# NV32F100 register map
File version: 1.6
Registers are 32-bit, read-write, reset 0x0 unless marked. A register's access mark holds for its fields unless they carry their own. Offsets are from the block's base; [hi:lo] are bit positions; {n}, {i} and the like mark numbered series.

## SMC — System Mode Controller
Base 0x4007E000; register names take the prefix SMC_
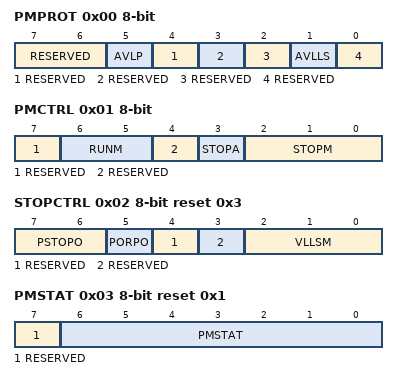
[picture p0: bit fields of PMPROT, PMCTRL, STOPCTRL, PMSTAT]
0x00 PMPROT 8-bit — Power Mode Protection register
  [7:6] RESERVED ro
  [5] AVLP — Allow Very-Low-Power Modes
    0=VLPR, VLPW and VLPS are not allowed; 1=VLPR, VLPW and VLPS are allowed
  [4] RESERVED ro
  [3] RESERVED ro
  [2] RESERVED ro
  [1] AVLLS — Allow Very-Low-Leakage Stop Mode
    0=Any VLLSx mode is not allowed; 1=Any VLLSx mode is allowed
  [0] RESERVED ro
0x01 PMCTRL 8-bit — Power Mode Control register
  [7] RESERVED ro
  [6:5] RUNM — Run Mode Control
    0=Normal Run mode (RUN); 2=Very-Low-Power Run mode (VLPR)
  [4] RESERVED ro
  [3] STOPA ro — Stop Aborted
    0=The previous stop mode entry was successsful; 1=The previous stop mode entry was aborted
  [2:0] STOPM — Stop Mode Control
    0=Normal Stop (STOP); 2=Very-Low-Power Stop (VLPS); 4=Very-Low-Leakage Stop (VLLSx); 6=Reseved
0x02 STOPCTRL 8-bit reset 0x3 — Stop Control Register
  [7:6] PSTOPO — Partial Stop Option
    0=STOP - Normal Stop mode; 1=PSTOP1 - Partial Stop with both system and bus clocks disabled; 2=PSTOP2 - Partial Stop with system clock disabled and bus clock enabled
  [5] PORPO — POR Power Option
    0=POR detect circuit is enabled in VLLS0; 1=POR detect circuit is disabled in VLLS0
  [4] RESERVED ro
  [3] RESERVED ro
  [2:0] VLLSM — VLLS Mode Control.
    0=VLLS0; 1=VLLS1; 3=VLLS3
0x03 PMSTAT 8-bit ro reset 0x1 — Power Mode Status register
  [7] RESERVED, [6:0] PMSTAT

## RCM — Reset Control Module
Base 0x4007F000; register names take the prefix RCM_
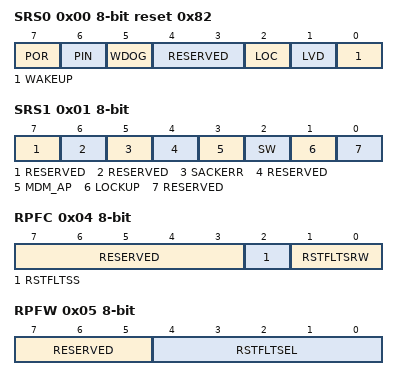
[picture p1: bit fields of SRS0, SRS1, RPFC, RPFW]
0x00 SRS0 8-bit ro reset 0x82 — System Reset Status Register 0
  [7] POR — Power-On Reset
    0=Reset not caused by POR; 1=Reset caused by POR
  [6] PIN — External Reset Pin
    0=Reset not caused by external reset pin; 1=Reset caused by external reset pin
  [5] WDOG — Watchdog
    0=Reset not caused by watchdog timeout; 1=Reset caused by watchdog timeout
  [4:3] RESERVED
  [2] LOC — Loss-of-Clock Reset
    0=Reset not caused by a loss of external clock; 1=Reset caused by a loss of external clock
  [1] LVD — Low-Voltage Detect Reset
    0=Reset not caused by LVD trip or POR; 1=Reset caused by LVD trip or POR
  [0] WAKEUP — Low Leakage Wakeup Reset
    0=Reset not caused by wakeup source; 1=Reset caused by wakeup source
0x01 SRS1 8-bit ro — System Reset Status Register 1
  [7] RESERVED
  [6] RESERVED
  [5] SACKERR — Stop Mode Acknowledge Error Reset
    0=Reset not caused by peripheral failure to acknowledge attempt to enter stop mode; 1=Reset caused by peripheral failure to acknowledge attempt to enter stop mode
  [4] RESERVED
  [3] MDM_AP — MDM-AP System Reset Request
    0=Reset not caused by host debugger system setting of the System Reset Request bit; 1=Reset caused by host debugger system setting of the System Reset Request bit
  [2] SW — Software
    0=Reset not caused by software setting of SYSRESETREQ bit; 1=Reset caused by software setting of SYSRESETREQ bit
  [1] LOCKUP — Core Lockup
    0=Reset not caused by core LOCKUP event; 1=Reset caused by core LOCKUP event
  [0] RESERVED
0x04 RPFC 8-bit — Reset Pin Filter Control register
  [7:3] RESERVED ro
  [2] RSTFLTSS — Reset Pin Filter Select in Stop Mode
    0=All filtering disabled; 1=LPO clock filter enabled
  [1:0] RSTFLTSRW — Reset Pin Filter Select in Run and Wait Modes
    0=All filtering disabled; 1=Bus clock filter enabled for normal operation; 2=LPO clock filter enabled for normal operation
0x05 RPFW 8-bit — Reset Pin Filter Width register
  [7:5] RESERVED ro
  [4:0] RSTFLTSEL — Reset Pin Filter Bus Clock Select
    {v}=Bus clock filter count is {v+1} (v=0..31)

## PTA — General Purpose Input/Output
Base 0x400FF000; register names take the prefix GPIOA_
0x00 PDOR — Port Data Output Register
  [31:0] PDO — Port Data Output
    0=Logic level 0 is driven on pin, provided pin is configured for general-purpose output; 1=Logic level 1 is driven on pin, provided pin is configured for general-purpose output
0x04 PSOR wo — Port Set Output Register
  [31:0] PTSO — Port Set Output
    0=Corresponding bit in PDORn does not change; 1=Corresponding bit in PDORn is set to logic 1
0x08 PCOR wo — Port Clear Output Register
  [31:0] PTCO — Port Clear Output
    0=Corresponding bit in PDORn does not change; 1=Corresponding bit in PDORn is cleared to logic 0
0x0C PTOR wo — Port Toggle Output Register
  [31:0] PTTO — Port Toggle Output
    0=Corresponding bit in PDORn does not change; 1=Corresponding bit in PDORn is set to the inverse of its existing logic state
0x10 PDIR ro — Port Data Input Register
  [31:0] PDI — Port Data Input
    0=Pin logic level is logic 0, or is not configured for use by digital function; 1=Pin logic level is logic 1
0x14 PDDR — Port Data Direction Register
  [31:0] PDD — Port Data Direction
    0=Pin is configured as general-purpose input, for the GPIO function; 1=Pin is configured as general-purpose output, for the GPIO function

## PTB — General Purpose Input/Output
Base 0x400FF040; register names take the prefix GPIOB_
Registers as PTA.

## FPTA — General Purpose Input/Output
Base 0xF80FF000; register names take the prefix FGPIOA_
Registers as PTA.

## FPTB — General Purpose Input/Output
Base 0xF80FF040; register names take the prefix FGPIOB_
Registers as PTA.
